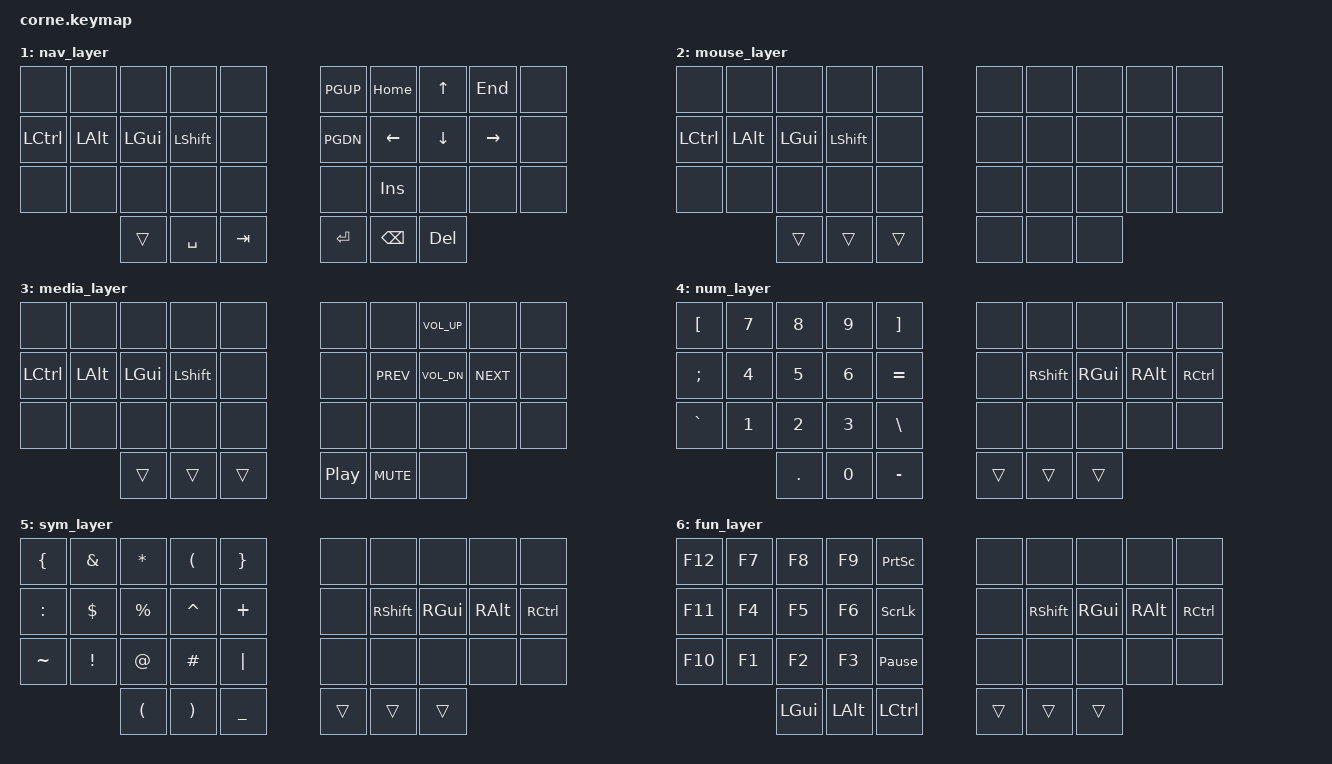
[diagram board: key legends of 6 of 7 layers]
/*
 * Copyright (c) 2020 The ZMK Contributors
 *
 * SPDX-License-Identifier: MIT
 */

#include <behaviors.dtsi>
#include <dt-bindings/zmk/keys.h>
#include <dt-bindings/zmk/bt.h>
#include <dt-bindings/zmk/rgb.h>
#include <dt-bindings/zmk/ext_power.h>

// Layer definitions
#define BASE 0
#define NAV 1
#define MOUSE 2
#define MEDIA 3
#define NUM 4
#define SYM 5
#define FUN 6

// Home row mods macro
#define HRML(k1,k2,k3,k4) &mt LCTRL k1  &mt LALT k2  &mt LGUI k3  &mt LSHFT k4
#define HRMR(k1,k2,k3,k4) &mt RSHFT k1  &mt RGUI k2  &mt RALT k3  &mt RCTRL k4

/ {
    behaviors {
        hm: homerow_mods {
            compatible = "zmk,behavior-hold-tap";
            label = "HOMEROW_MODS";
            #binding-cells = <2>;
            tapping-term-ms = <200>;
            quick-tap-ms = <0>;
            flavor = "tap-preferred";
            bindings = <&kp>, <&kp>;
        };
    };

    combos {
        compatible = "zmk,combos";
        combo_esc {
            timeout-ms = <50>;
            key-positions = <0 1>;
            bindings = <&kp ESC>;
        };
        
        combo_tab {
            timeout-ms = <50>;
            key-positions = <10 11>;
            bindings = <&kp TAB>;
        };
        
        combo_enter {
            timeout-ms = <50>;
            key-positions = <19 20>;
            bindings = <&kp ENTER>;
        };
        
        combo_backspace {
            timeout-ms = <50>;
            key-positions = <8 9>;
            bindings = <&kp BACKSPACE>;
        };
    };

    keymap {
        compatible = "zmk,keymap";

        default_layer {
            // ╭──────────┬──────────┬──────────┬──────────┬──────────┬──────────╮   ╭──────────┬──────────┬──────────┬──────────┬──────────┬──────────╮
            // │  Q       │  W       │  F       │  P       │  B       │          │   │          │  J       │  L       │  U       │  Y       │  '       │
            // ├──────────┼──────────┼──────────┼──────────┼──────────┼──────────┤   ├──────────┼──────────┼──────────┼──────────┼──────────┼──────────┤
            // │  A       │  R       │  S       │  T       │  G       │          │   │          │  M       │  N       │  E       │  I       │  O       │
            // ├──────────┼──────────┼──────────┼──────────┼──────────┼──────────┤   ├──────────┼──────────┼──────────┼──────────┼──────────┼──────────┤
            // │  Z       │  X       │  C       │  D       │  V       │          │   │          │  K       │  H       │  ,       │  .       │  /       │
            // ╰──────────┴──────────┴──────────┼──────────┼──────────┼──────────┤   ├──────────┼──────────┼──────────┼──────────┴──────────┴──────────╯
            //                                   │  MEDIA   │  NAV     │  MOUSE   │   │  NUM     │  SYM     │  FUN     │
            //                                   ╰──────────┴──────────┴──────────╯   ╰──────────┴──────────┴──────────╯
            bindings = <
                &kp Q      &kp W      &kp F      &kp P      &kp B                          &kp J      &kp L      &kp U      &kp Y      &kp SQT
                HRML(A,        R,         S,         T)     &kp G                          &kp M      HRMR(N,        E,         I,        O)
                &kp Z      &kp X      &kp C      &kp D      &kp V                          &kp K      &kp H      &kp COMMA  &kp DOT    &kp FSLH
                                   &lt MEDIA ESC  &lt NAV SPACE  &lt MOUSE TAB       &lt NUM ENTER  &lt SYM BSPC  &lt FUN DEL
            >;
        };

        nav_layer {
            // Navigation layer with cursor and selection controls
            bindings = <
                &none      &none      &none      &none      &none                          &kp PGUP   &kp HOME   &kp UP     &kp END    &none
                &kp LCTRL  &kp LALT   &kp LGUI   &kp LSHFT  &none                          &kp PGDN   &kp LEFT   &kp DOWN   &kp RIGHT  &none
                &none      &none      &none      &none      &none                          &none      &kp INS    &none      &none      &none
                                      &trans     &kp SPACE  &kp TAB                        &kp ENTER  &kp BSPC   &kp DEL
            >;
        };

        mouse_layer {
            // Mouse control layer (requires additional mouse keys support)
            bindings = <
                &none      &none      &none      &none      &none                          &none      &none      &none      &none      &none
                &kp LCTRL  &kp LALT   &kp LGUI   &kp LSHFT  &none                          &none      &none      &none      &none      &none
                &none      &none      &none      &none      &none                          &none      &none      &none      &none      &none
                                      &trans     &trans     &trans                         &none      &none      &none
            >;
        };

        media_layer {
            // Media controls and system functions
            bindings = <
                &none      &none      &none      &none      &none                          &none      &none      &kp C_VOL_UP &none     &none
                &kp LCTRL  &kp LALT   &kp LGUI   &kp LSHFT  &none                          &none      &kp C_PREV &kp C_VOL_DN &kp C_NEXT &none
                &none      &none      &none      &none      &none                          &none      &none      &none      &none      &none
                                      &trans     &trans     &trans                         &kp C_PP   &kp C_MUTE &none
            >;
        };

        num_layer {
            // Numbers and calculations
            bindings = <
                &kp LBKT   &kp N7     &kp N8     &kp N9     &kp RBKT                       &none      &none      &none      &none      &none
                &kp SEMI   &kp N4     &kp N5     &kp N6     &kp EQUAL                      &none      &kp RSHFT  &kp RGUI   &kp RALT   &kp RCTRL
                &kp GRAVE  &kp N1     &kp N2     &kp N3     &kp BSLH                       &none      &none      &none      &none      &none
                                      &kp DOT    &kp N0     &kp MINUS                      &trans     &trans     &trans
            >;
        };

        sym_layer {
            // Symbols for coding and text editing
            bindings = <
                &kp LBRC   &kp AMPS   &kp ASTRK  &kp LPAR   &kp RBRC                       &none      &none      &none      &none      &none
                &kp COLON  &kp DLLR   &kp PRCNT  &kp CARET  &kp PLUS                       &none      &kp RSHFT  &kp RGUI   &kp RALT   &kp RCTRL
                &kp TILDE  &kp EXCL   &kp AT     &kp HASH   &kp PIPE                       &none      &none      &none      &none      &none
                                      &kp LPAR   &kp RPAR   &kp UNDER                      &trans     &trans     &trans
            >;
        };

        fun_layer {
            // Function keys and system controls
            bindings = <
                &kp F12    &kp F7     &kp F8     &kp F9     &kp PSCRN                      &none      &none      &none      &none      &none
                &kp F11    &kp F4     &kp F5     &kp F6     &kp SLCK                       &none      &kp RSHFT  &kp RGUI   &kp RALT   &kp RCTRL
                &kp F10    &kp F1     &kp F2     &kp F3     &kp PAUSE_BREAK                &none      &none      &none      &none      &none
                                      &kp LGUI   &kp LALT   &kp LCTRL                      &trans     &trans     &trans
            >;
        };
    };
};
